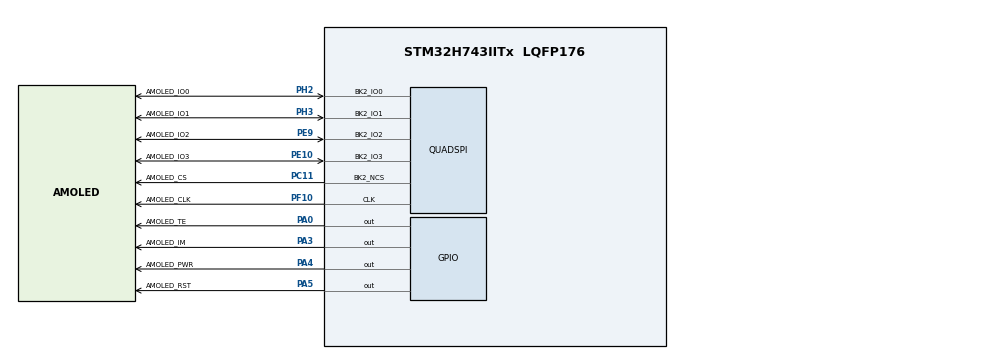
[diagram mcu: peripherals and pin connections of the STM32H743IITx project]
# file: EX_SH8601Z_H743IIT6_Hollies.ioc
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ADC3.Channel-0\#ChannelRegularConversion=ADC_CHANNEL_TEMPSENSOR
ADC3.NbrOfConversionFlag=1
ADC3.OffsetNumber-0\#ChannelRegularConversion=ADC_OFFSET_NONE
ADC3.OffsetSignedSaturation-0\#ChannelRegularConversion=DISABLE
ADC3.Rank-0\#ChannelRegularConversion=1
ADC3.SamplingTime-0\#ChannelRegularConversion=ADC_SAMPLETIME_810CYCLES_5
CORTEX_M7.AccessPermission_Spec=MPU_REGION_FULL_ACCESS
CORTEX_M7.BaseAddress_Spec=0x24000000
CORTEX_M7.CPU_DCache=Enabled
CORTEX_M7.CPU_ICache=Enabled
CORTEX_M7.DisableExec_Spec=MPU_INSTRUCTION_ACCESS_ENABLE
CORTEX_M7.IsBufferable_Spec=MPU_ACCESS_BUFFERABLE
CORTEX_M7.IsCacheable_Spec=MPU_ACCESS_CACHEABLE
CORTEX_M7.IsShareable_Spec=MPU_ACCESS_NOT_SHAREABLE
CORTEX_M7.Size_Spec=MPU_REGION_SIZE_512KB
CORTEX_M7.SubRegionDisable_Spec=0x0
CORTEX_M7.TypeExtField_Spec=MPU_TEX_LEVEL1
CORTEX_M7.default_mode_Activation=1
Mcu.Family=STM32H7
Mcu.Name=STM32H743IITx
Mcu.Package=LQFP176
NVIC.PriorityGroup=NVIC_PRIORITYGROUP_4
NVIC.TIM1_UP_IRQn=true\:15\:0\:false\:false\:true\:false\:true\:true
NVIC.TimeBase=TIM1_UP_IRQn
NVIC.TimeBaseIP=TIM1
PA0.GPIO_Label=AMOLED_TE
PA0.GPIO_Speed=GPIO_SPEED_FREQ_VERY_HIGH
PA0.Signal=GPIO_Output
PA13\ (JTMS/SWDIO).Mode=Serial_Wire
PA13\ (JTMS/SWDIO).Signal=DEBUG_JTMS-SWDIO
PA14\ (JTCK/SWCLK).Mode=Serial_Wire
PA14\ (JTCK/SWCLK).Signal=DEBUG_JTCK-SWCLK
PA3.GPIO_Label=AMOLED_IM
PA3.GPIO_Speed=GPIO_SPEED_FREQ_VERY_HIGH
PA3.Signal=GPIO_Output
PA4.GPIO_Label=AMOLED_PWR
PA4.GPIO_Speed=GPIO_SPEED_FREQ_VERY_HIGH
PA4.Signal=GPIO_Output
PA5.GPIO_Label=AMOLED_RST
PA5.GPIO_Speed=GPIO_SPEED_FREQ_VERY_HIGH
PA5.Signal=GPIO_Output
PC11.GPIO_Label=AMOLED_CS
PC11.GPIO_Speed=GPIO_SPEED_FREQ_VERY_HIGH
PC11.Mode=Single Bank 2
PC11.Signal=QUADSPI_BK2_NCS
PC14-OSC32_IN\ (OSC32_IN).Mode=LSE-External-Oscillator
PC14-OSC32_IN\ (OSC32_IN).Signal=RCC_OSC32_IN
PC15-OSC32_OUT\ (OSC32_OUT).Mode=LSE-External-Oscillator
PC15-OSC32_OUT\ (OSC32_OUT).Signal=RCC_OSC32_OUT
PE10.GPIO_Label=AMOLED_IO3
PE10.GPIO_Speed=GPIO_SPEED_FREQ_VERY_HIGH
PE10.Mode=Single Bank 2
PE10.Signal=QUADSPI_BK2_IO3
PE9.GPIO_Label=AMOLED_IO2
PE9.GPIO_Speed=GPIO_SPEED_FREQ_VERY_HIGH
PE9.Mode=Single Bank 2
PE9.Signal=QUADSPI_BK2_IO2
PF10.GPIO_Label=AMOLED_CLK
PF10.GPIO_Speed=GPIO_SPEED_FREQ_VERY_HIGH
PF10.Mode=Single Bank 2
PF10.Signal=QUADSPI_CLK
PH0-OSC_IN\ (PH0).Mode=HSE-External-Oscillator
PH0-OSC_IN\ (PH0).Signal=RCC_OSC_IN
PH1-OSC_OUT\ (PH1).Mode=HSE-External-Oscillator
PH1-OSC_OUT\ (PH1).Signal=RCC_OSC_OUT
PH2.GPIO_Label=AMOLED_IO0
PH2.GPIO_Speed=GPIO_SPEED_FREQ_VERY_HIGH
PH2.Mode=Single Bank 2
PH2.Signal=QUADSPI_BK2_IO0
PH3.GPIO_Label=AMOLED_IO1
PH3.GPIO_Speed=GPIO_SPEED_FREQ_VERY_HIGH
PH3.Mode=Single Bank 2
PH3.Signal=QUADSPI_BK2_IO1
ProjectManager.HeapSize=0x200
ProjectManager.StackSize=0x400
ProjectManager.TargetToolchain=STM32CubeIDE
QUADSPI.ClockPrescaler=5
QUADSPI.SampleShifting=QSPI_SAMPLE_SHIFTING_HALFCYCLE
RCC.ADCFreq_Value=75000000
RCC.APB1Freq_Value=120000000
RCC.APB2Freq_Value=120000000
RCC.APB3Freq_Value=120000000
RCC.APB4Freq_Value=120000000
RCC.CortexFreq_Value=480000000
RCC.D1PPRE=RCC_APB3_DIV2
RCC.D2PPRE1=RCC_APB1_DIV2
RCC.D2PPRE2=RCC_APB2_DIV2
RCC.D3PPRE=RCC_APB4_DIV2
RCC.DIVM1=5
RCC.DIVM2=2
RCC.DIVN1=192
RCC.DIVN2=12
RCC.HCLKFreq_Value=240000000
RCC.HPRE=RCC_HCLK_DIV2
RCC.PLL2FRACN=0
RCC.PLLFRACN=0
RCC.PLLSourceVirtual=RCC_PLLSOURCE_HSE
RCC.SYSCLKFreq_VALUE=480000000
RCC.SYSCLKSource=RCC_SYSCLKSOURCE_PLLCLK
RCC.USBFreq_Value=480000000
VP_ADC3_TempSens_Input.Mode=IN-TempSens
VP_SYS_VS_tim1.Mode=TIM1
board=custom

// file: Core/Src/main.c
/* USER CODE BEGIN Header */
/**
  ******************************************************************************
  * @file           : main.c
  * @brief          : Main program body
  ******************************************************************************
  * @attention
  *
  * Copyright (c) 2023 STMicroelectronics.
  * All rights reserved.
  *
  * This software is licensed under terms that can be found in the LICENSE file
  * in the root directory of this software component.
  * If no LICENSE file comes with this software, it is provided AS-IS.
  *
  ******************************************************************************
  */
/* USER CODE END Header */
#include "main.h"
#include "adc.h"
#include "quadspi.h"
#include "gpio.h"

/* USER CODE BEGIN Includes */
#include "amoled.h"
/* USER CODE END Includes */

void SystemClock_Config(void);
static void MPU_Config(void);

int main(void)
{

  /* MPU Configuration--------------------------------------------------------*/
  MPU_Config();
/* Enable the CPU Cache */

  /* Enable I-Cache---------------------------------------------------------*/
  SCB_EnableICache();

  /* Enable D-Cache---------------------------------------------------------*/
  SCB_EnableDCache();

  /* MCU Configuration--------------------------------------------------------*/

  /* Reset of all peripherals, Initializes the Flash interface and the Systick. */
  HAL_Init();

  /* Configure the system clock */
  SystemClock_Config();

  /* Initialize all configured peripherals */
  MX_GPIO_Init();
  MX_ADC3_Init();
  MX_QUADSPI_Init();

  /* Infinite loop */
  while (1)
  {

  }
}

void SystemClock_Config(void)
{
  RCC_OscInitTypeDef RCC_OscInitStruct = {0};
  RCC_ClkInitTypeDef RCC_ClkInitStruct = {0};

  /** Supply configuration update enable
  */
  HAL_PWREx_ConfigSupply(PWR_LDO_SUPPLY);

  /** Configure the main internal regulator output voltage
  */
  __HAL_PWR_VOLTAGESCALING_CONFIG(PWR_REGULATOR_VOLTAGE_SCALE1);

  while(!__HAL_PWR_GET_FLAG(PWR_FLAG_VOSRDY)) {}

  __HAL_RCC_SYSCFG_CLK_ENABLE();
  __HAL_PWR_VOLTAGESCALING_CONFIG(PWR_REGULATOR_VOLTAGE_SCALE0);

  while(!__HAL_PWR_GET_FLAG(PWR_FLAG_VOSRDY)) {}

  /** Initializes the RCC Oscillators according to the specified parameters
  * in the RCC_OscInitTypeDef structure.
  */
  RCC_OscInitStruct.OscillatorType = RCC_OSCILLATORTYPE_HSE;
  RCC_OscInitStruct.HSEState = RCC_HSE_ON;
  RCC_OscInitStruct.PLL.PLLState = RCC_PLL_ON;
  RCC_OscInitStruct.PLL.PLLSource = RCC_PLLSOURCE_HSE;
  RCC_OscInitStruct.PLL.PLLM = 5;
  RCC_OscInitStruct.PLL.PLLN = 192;
  RCC_OscInitStruct.PLL.PLLP = 2;
  RCC_OscInitStruct.PLL.PLLQ = 2;
  RCC_OscInitStruct.PLL.PLLR = 2;
  RCC_OscInitStruct.PLL.PLLRGE = RCC_PLL1VCIRANGE_2;
  RCC_OscInitStruct.PLL.PLLVCOSEL = RCC_PLL1VCOWIDE;
  RCC_OscInitStruct.PLL.PLLFRACN = 0;
  if (HAL_RCC_OscConfig(&RCC_OscInitStruct) != HAL_OK)
  {
    Error_Handler();
  }

  /** Initializes the CPU, AHB and APB buses clocks
  */
  RCC_ClkInitStruct.ClockType = RCC_CLOCKTYPE_HCLK|RCC_CLOCKTYPE_SYSCLK
                              |RCC_CLOCKTYPE_PCLK1|RCC_CLOCKTYPE_PCLK2
                              |RCC_CLOCKTYPE_D3PCLK1|RCC_CLOCKTYPE_D1PCLK1;
  RCC_ClkInitStruct.SYSCLKSource = RCC_SYSCLKSOURCE_PLLCLK;
  RCC_ClkInitStruct.SYSCLKDivider = RCC_SYSCLK_DIV1;
  RCC_ClkInitStruct.AHBCLKDivider = RCC_HCLK_DIV2;
  RCC_ClkInitStruct.APB3CLKDivider = RCC_APB3_DIV2;
  RCC_ClkInitStruct.APB1CLKDivider = RCC_APB1_DIV2;
  RCC_ClkInitStruct.APB2CLKDivider = RCC_APB2_DIV2;
  RCC_ClkInitStruct.APB4CLKDivider = RCC_APB4_DIV2;

  if (HAL_RCC_ClockConfig(&RCC_ClkInitStruct, FLASH_LATENCY_4) != HAL_OK)
  {
    Error_Handler();
  }
}

/* MPU Configuration */

void MPU_Config(void)
{
  MPU_Region_InitTypeDef MPU_InitStruct = {0};

  /* Disables the MPU */
  HAL_MPU_Disable();

  /** Initializes and configures the Region and the memory to be protected
  */
  MPU_InitStruct.Enable = MPU_REGION_ENABLE;
  MPU_InitStruct.Number = MPU_REGION_NUMBER0;
  MPU_InitStruct.BaseAddress = 0x24000000;
  MPU_InitStruct.Size = MPU_REGION_SIZE_512KB;
  MPU_InitStruct.SubRegionDisable = 0x0;
  MPU_InitStruct.TypeExtField = MPU_TEX_LEVEL1;
  MPU_InitStruct.AccessPermission = MPU_REGION_FULL_ACCESS;
  MPU_InitStruct.DisableExec = MPU_INSTRUCTION_ACCESS_ENABLE;
  MPU_InitStruct.IsShareable = MPU_ACCESS_NOT_SHAREABLE;
  MPU_InitStruct.IsCacheable = MPU_ACCESS_CACHEABLE;
  MPU_InitStruct.IsBufferable = MPU_ACCESS_BUFFERABLE;

  HAL_MPU_ConfigRegion(&MPU_InitStruct);
  /* Enables the MPU */
  HAL_MPU_Enable(MPU_PRIVILEGED_DEFAULT);

}

void HAL_TIM_PeriodElapsedCallback(TIM_HandleTypeDef *htim)
{
  if (htim->Instance == TIM1) {
    HAL_IncTick();
  }
}

void Error_Handler(void)
{
  __disable_irq();
  while (1)
  {
  }
}
